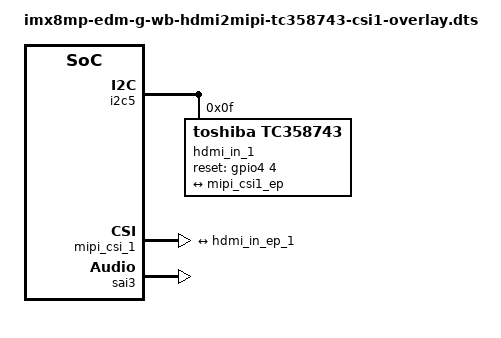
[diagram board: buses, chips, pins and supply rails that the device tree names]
// SPDX-License-Identifier: (GPL-2.0+ OR MIT)
/*
 * Copyright 2020 Technexion Ltd.
 *
 * Author: Ray Chang <ray.chang@technexion.com>
 *
 */

/******************************************************************************

USAGE NOTES:

This overlay is to enable 2 VizionLink HDMI boards connected into both camera
slots of the Wandboard-EDM-G baseboard.

It enables the TC358743 devices and logically connects them into the MIPI-CSI
ports of the i.MX8M Plus SOC. It also explicitly disables the TEVI-OV5640
cameras which are enabled by default on both CSI ports for the Wandboard-EDM-G.

It also disables the WM8960 codec, which is shared with SAI3 (SAI3 is named
AUD_A in the EDM-G-IMX8M-PLUS connection pinout). SAI3 is also the default
interface connected to the CAMERA1 port of the Wandboard-EDM-G.

This overlay can be included by configuring the 'dtoverlay' in u-boot to
include "hdmi2mipi-tc358743-csi1":

setenv dtoverlay ${dtoverlay} hdmi2mipi-tc358743-csi1
saveenv

*****************************************************************************/

/dts-v1/;
/plugin/;

#include <dt-bindings/interrupt-controller/irq.h>
#include <dt-bindings/gpio/gpio.h>

/ {
	fragment@0 {
		target = <&i2c5>;
		__overlay__ {
			#address-cells = <1>;
			#size-cells = <0>;
			status = "okay";

			hdmi_in_1: tc358743@f {
				compatible = "toshiba,tc358743";
				reg = <0x0f>;
				pinctrl-names = "default";
				pinctrl-0 = <&pinctrl_csi1_pwn>, <&pinctrl_csi1_rst>;
				reset-gpios = <&gpio4 4 GPIO_ACTIVE_HIGH>;
				status = "okay";
				port {
					hdmi_in_ep_1: endpoint {
						remote-endpoint = <&mipi_csi1_ep>;
						data-lanes = <1 2 3 4>;
						clock-lanes = <0>;
						clock-noncontinuous;
						link-frequencies = /bits/ 64 <297000000>;
					};
				};
			};
		};
	};

	fragment@1 {
		target = <&mipi_csi_1>;
		__overlay__ {
			#address-cells = <1>;
			#size-cells = <0>;
			status = "okay";
			port@1 {
				reg = <1>;
				mipi_csi1_ep: endpoint {
					remote-endpoint = <&hdmi_in_ep_1>;
					data-lanes = <4>;
					csis-hs-settle = <13>;
					csis-clk-settle = <2>;
					csis-wclk;
				};
			};
		};
	};

	fragment@2 {
		target-path = "/";
		__overlay__ {
			sound-wm8960 {
				status = "disabled";
			};

			sound-tc358743-csi1 {
				compatible = "nxp,imx-audio-tc358743", "nxp,imx-tc358743";
				cpu-dai = <&sai3>;
				nxp,audio-codec = <&hdmi_in_1>;
				//clocks = <&clk IMX8MP_CLK_SAI3>;
			};
		};
	};

	fragment@3 {
		target = <&sai3>;
		__overlay__ {
			status = "okay";
		};
	};
};

